AUTOSAR XML (schema 00044)
package /E40_Platform_System_SystemPackage/Components
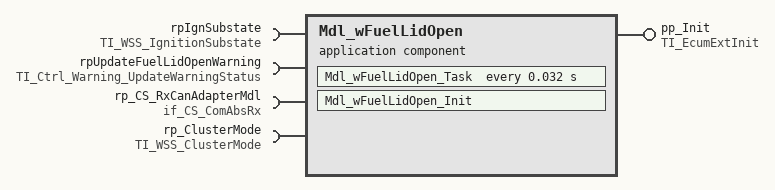
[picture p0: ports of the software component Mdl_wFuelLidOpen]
  application sw component type Mdl_wFuelLidOpen
    provide port pp_Init: server-com-spec{operation=Init, queue-length=1}, provided-interface=TI_EcumExtInit
    4 x require port:
      rpIgnSubstate: nonqueued-receiver-com-spec{data-element=IgnitionSubstate, init-value=constant-reference=Mdl_wFuelLidOpenIgnitionSubstateValue0}, required-interface=TI_WSS_IgnitionSubstate
      rpUpdateFuelLidOpenWarning: client-com-spec=UpdateWarningStatus, required-interface=TI_Ctrl_Warning_UpdateWarningStatus
      rp_CS_RxCanAdapterMdl: required-interface=if_CS_ComAbsRx
        required-com-specs:
          RxCan_GetSignalValue
          RxCan_GetSignalValueU8Arr
          RxCan_SetSignalInitValue
          RxCan_SetSignalInitValueU8Arr
          RxCan_SignalClearJustRcvdStatus
          RxCan_SignalGetJustRcvdStatus
          RxCan_SignalInvalidProcessingControl
          RxCan_SignalMissingProcessingControl
          RxCan_SignalNRProcessingControl
      rp_ClusterMode: nonqueued-receiver-com-spec{data-element=WSSCurrentClusterMode, init-value=constant-reference=Mdl_wFuelLidOpenWSSCurrentClusterModeValue0}, required-interface=TI_WSS_ClusterMode
    behavior IB_Mdl_wFuelLidOpen
      operation invoked event OIE_pp_Init_Mdl_wFuelLidOpen_InitTrigByInit: start-on-event=Mdl_wFuelLidOpen_Init, operation=pp_Init.Init
      timing event TEMdl_wFuelLidOpen_Task: start-on-event=Mdl_wFuelLidOpen_Task, period=0.032
      port-api-options:
        enable-take-address=false, indirect-api=false, port=pp_Init
        enable-take-address=false, indirect-api=false, port=rpIgnSubstate
        enable-take-address=false, indirect-api=false, port=rpUpdateFuelLidOpenWarning
        enable-take-address=false, indirect-api=false, port=rp_CS_RxCanAdapterMdl
        enable-take-address=false, indirect-api=false, port=rp_ClusterMode
      runnable Mdl_wFuelLidOpen_Init: can-be-invoked-concurrently=true
      runnable Mdl_wFuelLidOpen_Task: can-be-invoked-concurrently=true
        data-receive-point-by-arguments:
          access DRA_rpIgnSubstate_IgnitionSubstate: accessed-variable=rpIgnSubstate.IgnitionSubstate
          access DRA_rp_ClusterMode_WSSCurrentClusterMode: accessed-variable=rp_ClusterMode.WSSCurrentClusterMode
        10 x sync call:
          OA_rpUpdateFuelLidOpenWarning_UpdateWarningStatus: operation=rpUpdateFuelLidOpenWarning.UpdateWarningStatus
          OA_rp_CS_RxCanAdapterMdl_RxCan_GetSignalValueU8Arr: operation=rp_CS_RxCanAdapterMdl.RxCan_GetSignalValueU8Arr
          OA_rp_CS_RxCanAdapterMdl_RxCan_SetSignalInitValue: operation=rp_CS_RxCanAdapterMdl.RxCan_SetSignalInitValue
          OA_rp_CS_RxCanAdapterMdl_RxCan_SetSignalInitValueU8Arr: operation=rp_CS_RxCanAdapterMdl.RxCan_SetSignalInitValueU8Arr
          OA_rp_CS_RxCanAdapterMdl_RxCan_SignalInvalidProcessingControl: operation=rp_CS_RxCanAdapterMdl.RxCan_SignalInvalidProcessingControl
          OA_rp_CS_RxCanAdapterMdl_RxCan_SignalMissingProcessingControl: operation=rp_CS_RxCanAdapterMdl.RxCan_SignalMissingProcessingControl
          OA_rp_CS_RxCanAdapterMdl_RxCan_SignalNRProcessingControl: operation=rp_CS_RxCanAdapterMdl.RxCan_SignalNRProcessingControl
          OA_rp_CS_RxCanAdapterMdl_RxCan_SignalGetJustRcvdStatus: operation=rp_CS_RxCanAdapterMdl.RxCan_SignalGetJustRcvdStatus
          OA_rp_CS_RxCanAdapterMdl_RxCan_SignalClearJustRcvdStatus: operation=rp_CS_RxCanAdapterMdl.RxCan_SignalClearJustRcvdStatus
          OA_rp_CS_RxCanAdapterMdl_RxCan_GetSignalValue: operation=rp_CS_RxCanAdapterMdl.RxCan_GetSignalValue
  swc implementation IMPL_Mdl_wFuelLidOpen: behavior=IB_Mdl_wFuelLidOpen
